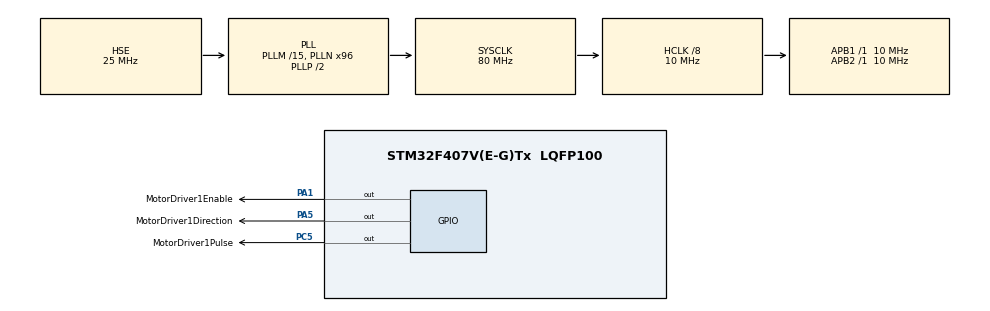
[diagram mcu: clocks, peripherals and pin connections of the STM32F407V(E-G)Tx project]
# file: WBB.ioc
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Mcu.Family=STM32F4
Mcu.Name=STM32F407V(E-G)Tx
Mcu.Package=LQFP100
NVIC.PriorityGroup=NVIC_PRIORITYGROUP_4
NVIC.TIM3_IRQn=true\:0\:0\:false\:false\:true\:true\:true
PA1.GPIO_Label=MotorDriver1Enable
PA1.Signal=GPIO_Output
PA5.GPIO_Label=MotorDriver1Direction
PA5.Signal=GPIO_Output
PC5.GPIO_Label=MotorDriver1Pulse
PC5.Signal=GPIO_Output
PH0-OSC_IN.GPIO_Label=Crystal_Occilator_In
PH0-OSC_IN.Mode=HSE-External-Oscillator
PH0-OSC_IN.Signal=RCC_OSC_IN
PH1-OSC_OUT.GPIO_Label=Crystal_Occilator_Out
PH1-OSC_OUT.Mode=HSE-External-Oscillator
PH1-OSC_OUT.Signal=RCC_OSC_OUT
ProjectManager.HeapSize=0x200
ProjectManager.StackSize=0x400
ProjectManager.TargetToolchain=SW4STM32
RCC.48MHZClocksFreq_Value=40000000
RCC.AHBCLKDivider=RCC_SYSCLK_DIV8
RCC.AHBFreq_Value=10000000
RCC.APB1Freq_Value=10000000
RCC.APB1TimFreq_Value=10000000
RCC.APB2Freq_Value=10000000
RCC.APB2TimFreq_Value=10000000
RCC.CortexFreq_Value=10000000
RCC.HCLKFreq_Value=10000000
RCC.HSE_VALUE=25000000
RCC.HSI_VALUE=16000000
RCC.LSE_VALUE=32768
RCC.PLLM=15
RCC.PLLN=96
RCC.PLLSourceVirtual=RCC_PLLSOURCE_HSE
RCC.SYSCLKFreq_VALUE=80000000
RCC.SYSCLKSource=RCC_SYSCLKSOURCE_PLLCLK
RCC.VCOOutputFreq_Value=160000000
TIM3.Channel-Output\ Compare1\ No\ Output=TIM_CHANNEL_1
TIM3.ClockDivision=TIM_CLOCKDIVISION_DIV1
TIM3.Period=100
TIM3.Prescaler=10000
VP_TIM3_VS_no_output1.Mode=Output Compare1 No Output
board=custom

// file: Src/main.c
/* USER CODE BEGIN Header */
/**
  ******************************************************************************
  * @file           : main.c
  * @brief          : Main program body
  ******************************************************************************
  * @attention
  *
  * <h2><center>&copy; Copyright (c) 2019 STMicroelectronics.
  * All rights reserved.</center></h2>
  *
  * This software component is licensed by ST under BSD 3-Clause license,
  * the "License"; You may not use this file except in compliance with the
  * License. You may obtain a copy of the License at:
  *                        opensource.org/licenses/BSD-3-Clause
  *
  ******************************************************************************
  */
/* USER CODE END Header */

#include "main.h"

/* USER CODE BEGIN Includes */
#include "WBBMain.h"
/* USER CODE END Includes */

TIM_HandleTypeDef htim3;

void SystemClock_Config(void);
static void MX_GPIO_Init(void);
static void MX_TIM3_Init(void);

int main(void)
{

  /* MCU Configuration--------------------------------------------------------*/

  /* Reset of all peripherals, Initializes the Flash interface and the Systick. */
  HAL_Init();

  /* Configure the system clock */
  SystemClock_Config();

  /* Initialize all configured peripherals */
  MX_GPIO_Init();
  MX_TIM3_Init();
  /* USER CODE BEGIN 2 */
  InitMotorDriver1TimerHandle(&htim3);
  /* USER CODE END 2 */

  /* Infinite loop */
  /* USER CODE BEGIN WHILE */
  while (1)
  {
	  WBBMain();
    /* USER CODE END WHILE */

  }
}

void SystemClock_Config(void)
{
  RCC_OscInitTypeDef RCC_OscInitStruct = {0};
  RCC_ClkInitTypeDef RCC_ClkInitStruct = {0};

  /** Configure the main internal regulator output voltage
  */
  __HAL_RCC_PWR_CLK_ENABLE();
  __HAL_PWR_VOLTAGESCALING_CONFIG(PWR_REGULATOR_VOLTAGE_SCALE1);
  /** Initializes the CPU, AHB and APB busses clocks
  */
  RCC_OscInitStruct.OscillatorType = RCC_OSCILLATORTYPE_HSE;
  RCC_OscInitStruct.HSEState = RCC_HSE_ON;
  RCC_OscInitStruct.PLL.PLLState = RCC_PLL_ON;
  RCC_OscInitStruct.PLL.PLLSource = RCC_PLLSOURCE_HSE;
  RCC_OscInitStruct.PLL.PLLM = 15;
  RCC_OscInitStruct.PLL.PLLN = 96;
  RCC_OscInitStruct.PLL.PLLP = RCC_PLLP_DIV2;
  RCC_OscInitStruct.PLL.PLLQ = 4;
  if (HAL_RCC_OscConfig(&RCC_OscInitStruct) != HAL_OK)
  {
    Error_Handler();
  }
  /** Initializes the CPU, AHB and APB busses clocks
  */
  RCC_ClkInitStruct.ClockType = RCC_CLOCKTYPE_HCLK|RCC_CLOCKTYPE_SYSCLK
                              |RCC_CLOCKTYPE_PCLK1|RCC_CLOCKTYPE_PCLK2;
  RCC_ClkInitStruct.SYSCLKSource = RCC_SYSCLKSOURCE_PLLCLK;
  RCC_ClkInitStruct.AHBCLKDivider = RCC_SYSCLK_DIV8;
  RCC_ClkInitStruct.APB1CLKDivider = RCC_HCLK_DIV1;
  RCC_ClkInitStruct.APB2CLKDivider = RCC_HCLK_DIV1;

  if (HAL_RCC_ClockConfig(&RCC_ClkInitStruct, FLASH_LATENCY_0) != HAL_OK)
  {
    Error_Handler();
  }
}

static void MX_TIM3_Init(void)
{

  TIM_MasterConfigTypeDef sMasterConfig = {0};
  TIM_OC_InitTypeDef sConfigOC = {0};

  htim3.Instance = TIM3;
  htim3.Init.Prescaler = 10000;
  htim3.Init.CounterMode = TIM_COUNTERMODE_UP;
  htim3.Init.Period = 100;
  htim3.Init.ClockDivision = TIM_CLOCKDIVISION_DIV1;
  htim3.Init.AutoReloadPreload = TIM_AUTORELOAD_PRELOAD_DISABLE;
  if (HAL_TIM_OC_Init(&htim3) != HAL_OK)
  {
    Error_Handler();
  }
  sMasterConfig.MasterOutputTrigger = TIM_TRGO_RESET;
  sMasterConfig.MasterSlaveMode = TIM_MASTERSLAVEMODE_DISABLE;
  if (HAL_TIMEx_MasterConfigSynchronization(&htim3, &sMasterConfig) != HAL_OK)
  {
    Error_Handler();
  }
  sConfigOC.OCMode = TIM_OCMODE_TIMING;
  sConfigOC.Pulse = 0;
  sConfigOC.OCPolarity = TIM_OCPOLARITY_HIGH;
  sConfigOC.OCFastMode = TIM_OCFAST_DISABLE;
  if (HAL_TIM_OC_ConfigChannel(&htim3, &sConfigOC, TIM_CHANNEL_1) != HAL_OK)
  {
    Error_Handler();
  }

}

static void MX_GPIO_Init(void)
{
  GPIO_InitTypeDef GPIO_InitStruct = {0};

  /* GPIO Ports Clock Enable */
  __HAL_RCC_GPIOH_CLK_ENABLE();
  __HAL_RCC_GPIOA_CLK_ENABLE();
  __HAL_RCC_GPIOC_CLK_ENABLE();

  /*Configure GPIO pin Output Level */
  HAL_GPIO_WritePin(GPIOA, MotorDriver1Enable_Pin|MotorDriver1Direction_Pin, GPIO_PIN_RESET);

  /*Configure GPIO pin Output Level */
  HAL_GPIO_WritePin(MotorDriver1Pulse_GPIO_Port, MotorDriver1Pulse_Pin, GPIO_PIN_RESET);

  /*Configure GPIO pins : MotorDriver1Enable_Pin MotorDriver1Direction_Pin */
  GPIO_InitStruct.Pin = MotorDriver1Enable_Pin|MotorDriver1Direction_Pin;
  GPIO_InitStruct.Mode = GPIO_MODE_OUTPUT_PP;
  GPIO_InitStruct.Pull = GPIO_NOPULL;
  GPIO_InitStruct.Speed = GPIO_SPEED_FREQ_LOW;
  HAL_GPIO_Init(GPIOA, &GPIO_InitStruct);

  /*Configure GPIO pin : MotorDriver1Pulse_Pin */
  GPIO_InitStruct.Pin = MotorDriver1Pulse_Pin;
  GPIO_InitStruct.Mode = GPIO_MODE_OUTPUT_PP;
  GPIO_InitStruct.Pull = GPIO_NOPULL;
  GPIO_InitStruct.Speed = GPIO_SPEED_FREQ_LOW;
  HAL_GPIO_Init(MotorDriver1Pulse_GPIO_Port, &GPIO_InitStruct);

}

void Error_Handler(void)
{
}

/************************ (C) COPYRIGHT STMicroelectronics *****END OF FILE****/
